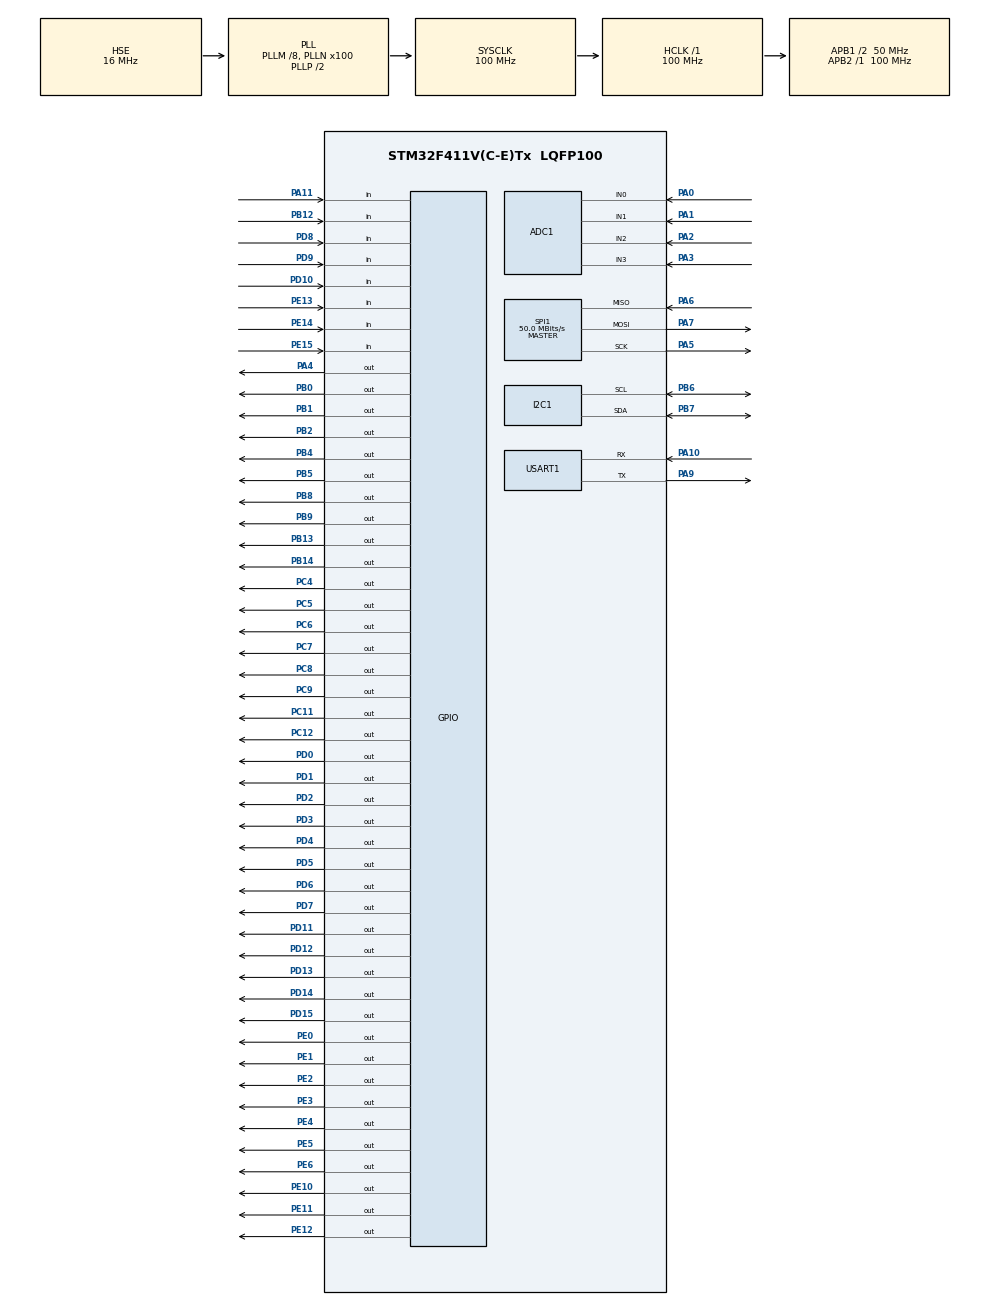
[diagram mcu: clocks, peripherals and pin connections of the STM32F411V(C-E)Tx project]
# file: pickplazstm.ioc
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Mcu.Family=STM32F4
PA6.Mode=Full_Duplex_Master
RCC.CortexFreq_Value=100000000
SPI1.VirtualType=VM_MASTER
SH.ADCx_IN2.0=ADC1_IN2,IN2
PC12.Signal=GPIO_Output
PB13.Signal=GPIO_Output
RCC.SYSCLKSource=RCC_SYSCLKSOURCE_PLLCLK
ProjectManager.StackSize=0x400
PD13.Signal=GPIO_Output
PH0\ -\ OSC_IN.Signal=RCC_OSC_IN
SPI1.Direction=SPI_DIRECTION_2LINES
RCC.HCLKFreq_Value=100000000
SH.ADCx_IN3.0=ADC1_IN3,IN3
PD4.Signal=GPIO_Output
RCC.APB2TimFreq_Value=100000000
TIM3.Period=10
PB6.Signal=I2C1_SCL
PC7.Signal=GPIO_Output
PB6.Mode=I2C
SPI1.CalculateBaudRate=50.0 MBits/s
PD0.Signal=GPIO_Output
PD8.Signal=GPIO_Input
PE5.Signal=GPIO_Output
PE1.Signal=GPIO_Output
RCC.AHBFreq_Value=100000000
Dma.USART1_RX.0.Priority=DMA_PRIORITY_LOW
ADC1.Channel-0\#ChannelRegularConversion=ADC_CHANNEL_0
RCC.HSE_VALUE=16000000
PB2.Signal=GPIO_Output
PE13.Signal=GPIO_Input
PA14.Mode=Serial_Wire
TIM3.Prescaler=99
PE2.Signal=GPIO_Output
PB7.Signal=I2C1_SDA
SH.ADCx_IN0.0=ADC1_IN0,IN0
TIM4.Period=1000
Dma.USART1_RX.0.MemInc=DMA_MINC_ENABLE
PE10.Signal=GPIO_Output
PE4.Signal=GPIO_Output
ADC1.SamplingTime-0\#ChannelRegularConversion=ADC_SAMPLETIME_3CYCLES
Mcu.Package=LQFP100
PB9.Signal=GPIO_Output
TIM2.Prescaler=99
PB1.Signal=GPIO_Output
PA6.Signal=SPI1_MISO
PD12.Signal=GPIO_Output
PA10.Signal=USART1_RX
Dma.USART1_RX.0.FIFOMode=DMA_FIFOMODE_DISABLE
SH.ADCx_IN1.0=ADC1_IN1,IN1
NVIC.DMA2_Stream2_IRQn=true\:0\:0\:false\:false\:true\:false\:true
RCC.APB1TimFreq_Value=100000000
Dma.USART1_RX.0.Mode=DMA_CIRCULAR
PC5.Signal=GPIO_Output
NVIC.USART1_IRQn=true\:0\:0\:false\:false\:true\:true\:true
PD6.Signal=GPIO_Output
Dma.Request0=USART1_RX
SPI1.BaudRatePrescaler=SPI_BAUDRATEPRESCALER_2
PD15.Signal=GPIO_Output
Dma.USART1_RX.0.Instance=DMA2_Stream2
VP_TIM3_VS_ClockSourceINT.Mode=Internal
PB4.Signal=GPIO_Output
PA3.Signal=ADCx_IN3
PA5.Mode=Full_Duplex_Master
RCC.PLLSourceVirtual=RCC_PLLSOURCE_HSE
TIM4.AutoReloadPreload=TIM_AUTORELOAD_PRELOAD_ENABLE
ADC1.Rank-0\#ChannelRegularConversion=1
PA7.Mode=Full_Duplex_Master
Dma.USART1_RX.0.PeriphDataAlignment=DMA_PDATAALIGN_BYTE
PA10.Mode=Asynchronous
TIM3.AutoReloadPreload=TIM_AUTORELOAD_PRELOAD_ENABLE
PC11.Signal=GPIO_Output
PD3.Signal=GPIO_Output
PH1\ -\ OSC_OUT.Mode=HSE-External-Oscillator
PC8.Signal=GPIO_Output
PC4.Signal=GPIO_Output
PC6.Signal=GPIO_Output
PD7.Signal=GPIO_Output
PD1.Signal=GPIO_Output
PD9.Signal=GPIO_Input
PD5.Signal=GPIO_Output
RCC.APB1CLKDivider=RCC_HCLK_DIV2
PA0-WKUP.Signal=ADCx_IN0
PD10.Signal=GPIO_Input
PA13.Signal=SYS_JTMS-SWDIO
PA9.Mode=Asynchronous
PH0\ -\ OSC_IN.Mode=HSE-External-Oscillator
ProjectManager.TargetToolchain=STM32CubeIDE
Dma.USART1_RX.0.Direction=DMA_PERIPH_TO_MEMORY
PA9.Signal=USART1_TX
TIM4.Prescaler=99
PE11.Signal=GPIO_Output
RCC.LSE_VALUE=32768
PA1.Signal=ADCx_IN1
Dma.USART1_RX.0.PeriphInc=DMA_PINC_DISABLE
PB14.Signal=GPIO_Output
PA5.Signal=SPI1_SCK
PH1\ -\ OSC_OUT.Signal=RCC_OSC_OUT
board=custom
RCC.VCOOutputFreq_Value=200000000
NVIC.TIM3_IRQn=true\:0\:0\:false\:false\:true\:true\:true
NVIC.SPI1_IRQn=true\:0\:0\:false\:false\:true\:true\:true
RCC.APB2Freq_Value=100000000
PE14.Signal=GPIO_Input
PE15.Signal=GPIO_Input
VP_TIM2_VS_ClockSourceINT.Mode=Internal
SPI1.Mode=SPI_MODE_MASTER
Dma.USART1_RX.0.MemDataAlignment=DMA_MDATAALIGN_BYTE
PE6.Signal=GPIO_Output
PA13.Mode=Serial_Wire
Mcu.Name=STM32F411V(C-E)Tx
PE0.Signal=GPIO_Output
PE12.Signal=GPIO_Output
PA2.Signal=ADCx_IN2
PD14.Signal=GPIO_Output
RCC.48MHZClocksFreq_Value=50000000
PA4.Signal=GPIO_Output
RCC.SYSCLKFreq_VALUE=100000000
PB5.Signal=GPIO_Output
ADC1.master=1
PD11.Signal=GPIO_Output
USART1.VirtualMode=VM_ASYNC
PA11.Signal=GPIO_Input
PB7.Mode=I2C
PA14.Signal=SYS_JTCK-SWCLK
ProjectManager.HeapSize=0x200
RCC.HSI_VALUE=16000000
VP_TIM4_VS_ClockSourceINT.Mode=Internal
NVIC.PriorityGroup=NVIC_PRIORITYGROUP_4
ADC1.NbrOfConversionFlag=1
RCC.PLLM=8
RCC.PLLN=100
PE3.Signal=GPIO_Output
PB8.Signal=GPIO_Output
TIM2.AutoReloadPreload=TIM_AUTORELOAD_PRELOAD_ENABLE
PC9.Signal=GPIO_Output
PD2.Signal=GPIO_Output
NVIC.TIM4_IRQn=true\:0\:0\:false\:false\:true\:true\:true
RCC.APB1Freq_Value=50000000
PB0.Signal=GPIO_Output
PB12.Signal=GPIO_Input
PA7.Signal=SPI1_MOSI

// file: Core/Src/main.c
/* USER CODE BEGIN Header */
/**
  ******************************************************************************
  * @file           : main.c
  * @brief          : Main program body
  ******************************************************************************
  * @attention
  *
  * <h2><center>&copy; Copyright (c) 2021 STMicroelectronics.
  * All rights reserved.</center></h2>
  *
  * This software component is licensed by ST under BSD 3-Clause license,
  * the "License"; You may not use this file except in compliance with the
  * License. You may obtain a copy of the License at:
  *                        opensource.org/licenses/BSD-3-Clause
  *
  ******************************************************************************
  */
/* USER CODE END Header */
#include "main.h"

/* USER CODE BEGIN Includes */
#include "app.h"
/* USER CODE END Includes */

ADC_HandleTypeDef hadc1;

I2C_HandleTypeDef hi2c1;

SPI_HandleTypeDef hspi1;

TIM_HandleTypeDef htim2;
TIM_HandleTypeDef htim3;
TIM_HandleTypeDef htim4;

UART_HandleTypeDef huart1;
DMA_HandleTypeDef hdma_usart1_rx;

void SystemClock_Config(void);
static void MX_GPIO_Init(void);
static void MX_DMA_Init(void);
static void MX_ADC1_Init(void);
static void MX_SPI1_Init(void);
static void MX_USART1_UART_Init(void);
static void MX_I2C1_Init(void);
static void MX_TIM2_Init(void);
static void MX_TIM3_Init(void);
static void MX_TIM4_Init(void);

int main(void)
{

  /* MCU Configuration--------------------------------------------------------*/

  /* Reset of all peripherals, Initializes the Flash interface and the Systick. */
  HAL_Init();

  /* Configure the system clock */
  SystemClock_Config();

  /* Initialize all configured peripherals */
  MX_GPIO_Init();
  MX_DMA_Init();
  MX_ADC1_Init();
  MX_SPI1_Init();
  MX_USART1_UART_Init();
  MX_I2C1_Init();
  MX_TIM2_Init();
  MX_TIM3_Init();
  MX_TIM4_Init();

  /* Infinite loop */
  /* USER CODE BEGIN WHILE */
  setup();

  HAL_TIM_Base_Start_IT(&htim2);  //timer has no used interrupt, but counter counts in 1us interval and overflows after 2^32
  htim3.Instance->ARR = 20-1;
  HAL_TIM_Base_Start_IT(&htim3);  //25us timer for fast program handling stuff
  htim4.Instance->ARR = 1000-1;
  HAL_TIM_Base_Start_IT(&htim4);  //1ms  timer for time program handling stuff

  while (1)
  {
	  __WFI();
	  loop();
    /* USER CODE END WHILE */

  }
}

void SystemClock_Config(void)
{
  RCC_OscInitTypeDef RCC_OscInitStruct = {0};
  RCC_ClkInitTypeDef RCC_ClkInitStruct = {0};

  /** Configure the main internal regulator output voltage
  */
  __HAL_RCC_PWR_CLK_ENABLE();
  __HAL_PWR_VOLTAGESCALING_CONFIG(PWR_REGULATOR_VOLTAGE_SCALE1);
  /** Initializes the RCC Oscillators according to the specified parameters
  * in the RCC_OscInitTypeDef structure.
  */
  RCC_OscInitStruct.OscillatorType = RCC_OSCILLATORTYPE_HSE;
  RCC_OscInitStruct.HSEState = RCC_HSE_ON;
  RCC_OscInitStruct.PLL.PLLState = RCC_PLL_ON;
  RCC_OscInitStruct.PLL.PLLSource = RCC_PLLSOURCE_HSE;
  RCC_OscInitStruct.PLL.PLLM = 8;
  RCC_OscInitStruct.PLL.PLLN = 100;
  RCC_OscInitStruct.PLL.PLLP = RCC_PLLP_DIV2;
  RCC_OscInitStruct.PLL.PLLQ = 4;
  if (HAL_RCC_OscConfig(&RCC_OscInitStruct) != HAL_OK)
  {
    Error_Handler();
  }
  /** Initializes the CPU, AHB and APB buses clocks
  */
  RCC_ClkInitStruct.ClockType = RCC_CLOCKTYPE_HCLK|RCC_CLOCKTYPE_SYSCLK
                              |RCC_CLOCKTYPE_PCLK1|RCC_CLOCKTYPE_PCLK2;
  RCC_ClkInitStruct.SYSCLKSource = RCC_SYSCLKSOURCE_PLLCLK;
  RCC_ClkInitStruct.AHBCLKDivider = RCC_SYSCLK_DIV1;
  RCC_ClkInitStruct.APB1CLKDivider = RCC_HCLK_DIV2;
  RCC_ClkInitStruct.APB2CLKDivider = RCC_HCLK_DIV1;

  if (HAL_RCC_ClockConfig(&RCC_ClkInitStruct, FLASH_LATENCY_3) != HAL_OK)
  {
    Error_Handler();
  }
}

static void MX_ADC1_Init(void)
{

  ADC_ChannelConfTypeDef sConfig = {0};

  /** Configure the global features of the ADC (Clock, Resolution, Data Alignment and number of conversion)
  */
  hadc1.Instance = ADC1;
  hadc1.Init.ClockPrescaler = ADC_CLOCK_SYNC_PCLK_DIV4;
  hadc1.Init.Resolution = ADC_RESOLUTION_12B;
  hadc1.Init.ScanConvMode = DISABLE;
  hadc1.Init.ContinuousConvMode = DISABLE;
  hadc1.Init.DiscontinuousConvMode = DISABLE;
  hadc1.Init.ExternalTrigConvEdge = ADC_EXTERNALTRIGCONVEDGE_NONE;
  hadc1.Init.ExternalTrigConv = ADC_SOFTWARE_START;
  hadc1.Init.DataAlign = ADC_DATAALIGN_RIGHT;
  hadc1.Init.NbrOfConversion = 1;
  hadc1.Init.DMAContinuousRequests = DISABLE;
  hadc1.Init.EOCSelection = ADC_EOC_SINGLE_CONV;
  if (HAL_ADC_Init(&hadc1) != HAL_OK)
  {
    Error_Handler();
  }
  /** Configure for the selected ADC regular channel its corresponding rank in the sequencer and its sample time.
  */
  sConfig.Channel = ADC_CHANNEL_0;
  sConfig.Rank = 1;
  sConfig.SamplingTime = ADC_SAMPLETIME_3CYCLES;
  if (HAL_ADC_ConfigChannel(&hadc1, &sConfig) != HAL_OK)
  {
    Error_Handler();
  }

}

static void MX_I2C1_Init(void)
{

  hi2c1.Instance = I2C1;
  hi2c1.Init.ClockSpeed = 100000;
  hi2c1.Init.DutyCycle = I2C_DUTYCYCLE_2;
  hi2c1.Init.OwnAddress1 = 0;
  hi2c1.Init.AddressingMode = I2C_ADDRESSINGMODE_7BIT;
  hi2c1.Init.DualAddressMode = I2C_DUALADDRESS_DISABLE;
  hi2c1.Init.OwnAddress2 = 0;
  hi2c1.Init.GeneralCallMode = I2C_GENERALCALL_DISABLE;
  hi2c1.Init.NoStretchMode = I2C_NOSTRETCH_DISABLE;
  if (HAL_I2C_Init(&hi2c1) != HAL_OK)
  {
    Error_Handler();
  }

}

static void MX_SPI1_Init(void)
{

  /* SPI1 parameter configuration*/
  hspi1.Instance = SPI1;
  hspi1.Init.Mode = SPI_MODE_MASTER;
  hspi1.Init.Direction = SPI_DIRECTION_2LINES;
  hspi1.Init.DataSize = SPI_DATASIZE_8BIT;
  hspi1.Init.CLKPolarity = SPI_POLARITY_LOW;
  hspi1.Init.CLKPhase = SPI_PHASE_1EDGE;
  hspi1.Init.NSS = SPI_NSS_SOFT;
  hspi1.Init.BaudRatePrescaler = SPI_BAUDRATEPRESCALER_2;
  hspi1.Init.FirstBit = SPI_FIRSTBIT_MSB;
  hspi1.Init.TIMode = SPI_TIMODE_DISABLE;
  hspi1.Init.CRCCalculation = SPI_CRCCALCULATION_DISABLE;
  hspi1.Init.CRCPolynomial = 10;
  if (HAL_SPI_Init(&hspi1) != HAL_OK)
  {
    Error_Handler();
  }

}

static void MX_TIM2_Init(void)
{

  TIM_ClockConfigTypeDef sClockSourceConfig = {0};
  TIM_MasterConfigTypeDef sMasterConfig = {0};

  htim2.Instance = TIM2;
  htim2.Init.Prescaler = 99;
  htim2.Init.CounterMode = TIM_COUNTERMODE_UP;
  htim2.Init.Period = 4294967295;
  htim2.Init.ClockDivision = TIM_CLOCKDIVISION_DIV1;
  htim2.Init.AutoReloadPreload = TIM_AUTORELOAD_PRELOAD_ENABLE;
  if (HAL_TIM_Base_Init(&htim2) != HAL_OK)
  {
    Error_Handler();
  }
  sClockSourceConfig.ClockSource = TIM_CLOCKSOURCE_INTERNAL;
  if (HAL_TIM_ConfigClockSource(&htim2, &sClockSourceConfig) != HAL_OK)
  {
    Error_Handler();
  }
  sMasterConfig.MasterOutputTrigger = TIM_TRGO_RESET;
  sMasterConfig.MasterSlaveMode = TIM_MASTERSLAVEMODE_DISABLE;
  if (HAL_TIMEx_MasterConfigSynchronization(&htim2, &sMasterConfig) != HAL_OK)
  {
    Error_Handler();
  }

}

static void MX_TIM3_Init(void)
{

  TIM_ClockConfigTypeDef sClockSourceConfig = {0};
  TIM_MasterConfigTypeDef sMasterConfig = {0};

  htim3.Instance = TIM3;
  htim3.Init.Prescaler = 99;
  htim3.Init.CounterMode = TIM_COUNTERMODE_UP;
  htim3.Init.Period = 10;
  htim3.Init.ClockDivision = TIM_CLOCKDIVISION_DIV1;
  htim3.Init.AutoReloadPreload = TIM_AUTORELOAD_PRELOAD_ENABLE;
  if (HAL_TIM_Base_Init(&htim3) != HAL_OK)
  {
    Error_Handler();
  }
  sClockSourceConfig.ClockSource = TIM_CLOCKSOURCE_INTERNAL;
  if (HAL_TIM_ConfigClockSource(&htim3, &sClockSourceConfig) != HAL_OK)
  {
    Error_Handler();
  }
  sMasterConfig.MasterOutputTrigger = TIM_TRGO_RESET;
  sMasterConfig.MasterSlaveMode = TIM_MASTERSLAVEMODE_DISABLE;
  if (HAL_TIMEx_MasterConfigSynchronization(&htim3, &sMasterConfig) != HAL_OK)
  {
    Error_Handler();
  }

}

static void MX_TIM4_Init(void)
{

  TIM_ClockConfigTypeDef sClockSourceConfig = {0};
  TIM_MasterConfigTypeDef sMasterConfig = {0};

  htim4.Instance = TIM4;
  htim4.Init.Prescaler = 99;
  htim4.Init.CounterMode = TIM_COUNTERMODE_UP;
  htim4.Init.Period = 1000;
  htim4.Init.ClockDivision = TIM_CLOCKDIVISION_DIV1;
  htim4.Init.AutoReloadPreload = TIM_AUTORELOAD_PRELOAD_ENABLE;
  if (HAL_TIM_Base_Init(&htim4) != HAL_OK)
  {
    Error_Handler();
  }
  sClockSourceConfig.ClockSource = TIM_CLOCKSOURCE_INTERNAL;
  if (HAL_TIM_ConfigClockSource(&htim4, &sClockSourceConfig) != HAL_OK)
  {
    Error_Handler();
  }
  sMasterConfig.MasterOutputTrigger = TIM_TRGO_RESET;
  sMasterConfig.MasterSlaveMode = TIM_MASTERSLAVEMODE_DISABLE;
  if (HAL_TIMEx_MasterConfigSynchronization(&htim4, &sMasterConfig) != HAL_OK)
  {
    Error_Handler();
  }

}

static void MX_USART1_UART_Init(void)
{

  huart1.Instance = USART1;
  huart1.Init.BaudRate = 115200;
  huart1.Init.WordLength = UART_WORDLENGTH_8B;
  huart1.Init.StopBits = UART_STOPBITS_1;
  huart1.Init.Parity = UART_PARITY_NONE;
  huart1.Init.Mode = UART_MODE_TX_RX;
  huart1.Init.HwFlowCtl = UART_HWCONTROL_NONE;
  huart1.Init.OverSampling = UART_OVERSAMPLING_16;
  if (HAL_UART_Init(&huart1) != HAL_OK)
  {
    Error_Handler();
  }

}

static void MX_DMA_Init(void)
{

  /* DMA controller clock enable */
  __HAL_RCC_DMA2_CLK_ENABLE();

  /* DMA interrupt init */
  /* DMA2_Stream2_IRQn interrupt configuration */
  HAL_NVIC_SetPriority(DMA2_Stream2_IRQn, 0, 0);
  HAL_NVIC_EnableIRQ(DMA2_Stream2_IRQn);

}

static void MX_GPIO_Init(void)
{
  GPIO_InitTypeDef GPIO_InitStruct = {0};

  /* GPIO Ports Clock Enable */
  __HAL_RCC_GPIOE_CLK_ENABLE();
  __HAL_RCC_GPIOH_CLK_ENABLE();
  __HAL_RCC_GPIOA_CLK_ENABLE();
  __HAL_RCC_GPIOC_CLK_ENABLE();
  __HAL_RCC_GPIOB_CLK_ENABLE();
  __HAL_RCC_GPIOD_CLK_ENABLE();

  /*Configure GPIO pin Output Level */
  HAL_GPIO_WritePin(GPIOE, GPIO_PIN_2|GPIO_PIN_3|GPIO_PIN_4|GPIO_PIN_5
                          |GPIO_PIN_6|GPIO_PIN_10|GPIO_PIN_11|GPIO_PIN_12
                          |GPIO_PIN_0|GPIO_PIN_1, GPIO_PIN_RESET);

  /*Configure GPIO pin Output Level */
  HAL_GPIO_WritePin(GPIOA, GPIO_PIN_4, GPIO_PIN_RESET);

  /*Configure GPIO pin Output Level */
  HAL_GPIO_WritePin(GPIOC, GPIO_PIN_4|GPIO_PIN_5|GPIO_PIN_6|GPIO_PIN_7
                          |GPIO_PIN_8|GPIO_PIN_9|GPIO_PIN_11|GPIO_PIN_12, GPIO_PIN_RESET);

  /*Configure GPIO pin Output Level */
  HAL_GPIO_WritePin(GPIOB, GPIO_PIN_0|GPIO_PIN_1|GPIO_PIN_2|GPIO_PIN_13
                          |GPIO_PIN_14|GPIO_PIN_4|GPIO_PIN_5|GPIO_PIN_8
                          |GPIO_PIN_9, GPIO_PIN_RESET);

  /*Configure GPIO pin Output Level */
  HAL_GPIO_WritePin(GPIOD, GPIO_PIN_11|GPIO_PIN_12|GPIO_PIN_13|GPIO_PIN_14
                          |GPIO_PIN_15|GPIO_PIN_0|GPIO_PIN_1|GPIO_PIN_2
                          |GPIO_PIN_3|GPIO_PIN_4|GPIO_PIN_5|GPIO_PIN_6
                          |GPIO_PIN_7, GPIO_PIN_RESET);

  /*Configure GPIO pins : PE2 PE3 PE4 PE5
                           PE6 PE10 PE11 PE12
                           PE0 PE1 */
  GPIO_InitStruct.Pin = GPIO_PIN_2|GPIO_PIN_3|GPIO_PIN_4|GPIO_PIN_5
                          |GPIO_PIN_6|GPIO_PIN_10|GPIO_PIN_11|GPIO_PIN_12
                          |GPIO_PIN_0|GPIO_PIN_1;
  GPIO_InitStruct.Mode = GPIO_MODE_OUTPUT_PP;
  GPIO_InitStruct.Pull = GPIO_NOPULL;
  GPIO_InitStruct.Speed = GPIO_SPEED_FREQ_LOW;
  HAL_GPIO_Init(GPIOE, &GPIO_InitStruct);

  /*Configure GPIO pin : PA4 */
  GPIO_InitStruct.Pin = GPIO_PIN_4;
  GPIO_InitStruct.Mode = GPIO_MODE_OUTPUT_PP;
  GPIO_InitStruct.Pull = GPIO_NOPULL;
  GPIO_InitStruct.Speed = GPIO_SPEED_FREQ_LOW;
  HAL_GPIO_Init(GPIOA, &GPIO_InitStruct);

  /*Configure GPIO pins : PC4 PC5 PC6 PC7
                           PC8 PC9 PC11 PC12 */
  GPIO_InitStruct.Pin = GPIO_PIN_4|GPIO_PIN_5|GPIO_PIN_6|GPIO_PIN_7
                          |GPIO_PIN_8|GPIO_PIN_9|GPIO_PIN_11|GPIO_PIN_12;
  GPIO_InitStruct.Mode = GPIO_MODE_OUTPUT_PP;
  GPIO_InitStruct.Pull = GPIO_NOPULL;
  GPIO_InitStruct.Speed = GPIO_SPEED_FREQ_LOW;
  HAL_GPIO_Init(GPIOC, &GPIO_InitStruct);

  /*Configure GPIO pins : PB0 PB1 PB2 PB13
                           PB14 PB4 PB5 PB8
                           PB9 */
  GPIO_InitStruct.Pin = GPIO_PIN_0|GPIO_PIN_1|GPIO_PIN_2|GPIO_PIN_13
                          |GPIO_PIN_14|GPIO_PIN_4|GPIO_PIN_5|GPIO_PIN_8
                          |GPIO_PIN_9;
  GPIO_InitStruct.Mode = GPIO_MODE_OUTPUT_PP;
  GPIO_InitStruct.Pull = GPIO_NOPULL;
  GPIO_InitStruct.Speed = GPIO_SPEED_FREQ_LOW;
  HAL_GPIO_Init(GPIOB, &GPIO_InitStruct);

  /*Configure GPIO pins : PE13 PE14 PE15 */
  GPIO_InitStruct.Pin = GPIO_PIN_13|GPIO_PIN_14|GPIO_PIN_15;
  GPIO_InitStruct.Mode = GPIO_MODE_INPUT;
  GPIO_InitStruct.Pull = GPIO_NOPULL;
  HAL_GPIO_Init(GPIOE, &GPIO_InitStruct);

  /*Configure GPIO pin : PB12 */
  GPIO_InitStruct.Pin = GPIO_PIN_12;
  GPIO_InitStruct.Mode = GPIO_MODE_INPUT;
  GPIO_InitStruct.Pull = GPIO_NOPULL;
  HAL_GPIO_Init(GPIOB, &GPIO_InitStruct);

  /*Configure GPIO pins : PD8 PD9 PD10 */
  GPIO_InitStruct.Pin = GPIO_PIN_8|GPIO_PIN_9|GPIO_PIN_10;
  GPIO_InitStruct.Mode = GPIO_MODE_INPUT;
  GPIO_InitStruct.Pull = GPIO_NOPULL;
  HAL_GPIO_Init(GPIOD, &GPIO_InitStruct);

  /*Configure GPIO pins : PD11 PD12 PD13 PD14
                           PD15 PD0 PD1 PD2
                           PD3 PD4 PD5 PD6
                           PD7 */
  GPIO_InitStruct.Pin = GPIO_PIN_11|GPIO_PIN_12|GPIO_PIN_13|GPIO_PIN_14
                          |GPIO_PIN_15|GPIO_PIN_0|GPIO_PIN_1|GPIO_PIN_2
                          |GPIO_PIN_3|GPIO_PIN_4|GPIO_PIN_5|GPIO_PIN_6
                          |GPIO_PIN_7;
  GPIO_InitStruct.Mode = GPIO_MODE_OUTPUT_PP;
  GPIO_InitStruct.Pull = GPIO_NOPULL;
  GPIO_InitStruct.Speed = GPIO_SPEED_FREQ_LOW;
  HAL_GPIO_Init(GPIOD, &GPIO_InitStruct);

  /*Configure GPIO pin : PA11 */
  GPIO_InitStruct.Pin = GPIO_PIN_11;
  GPIO_InitStruct.Mode = GPIO_MODE_INPUT;
  GPIO_InitStruct.Pull = GPIO_NOPULL;
  HAL_GPIO_Init(GPIOA, &GPIO_InitStruct);

}

void Error_Handler(void)
{
  __disable_irq();
  while (1)
  {
  }
}

/************************ (C) COPYRIGHT STMicroelectronics *****END OF FILE****/
